# MSP430FR5739 register map
File version: 1.1
CPU: msp430
Registers are 16-bit, access not given, reset 0x0 unless marked. A register's access mark holds for its fields unless they carry their own. Offsets are from the block's base; [hi:lo] are bit positions; {n}, {i} and the like mark numbered series.

## USCI_A0__SPI_Mode
Base 0x00000000
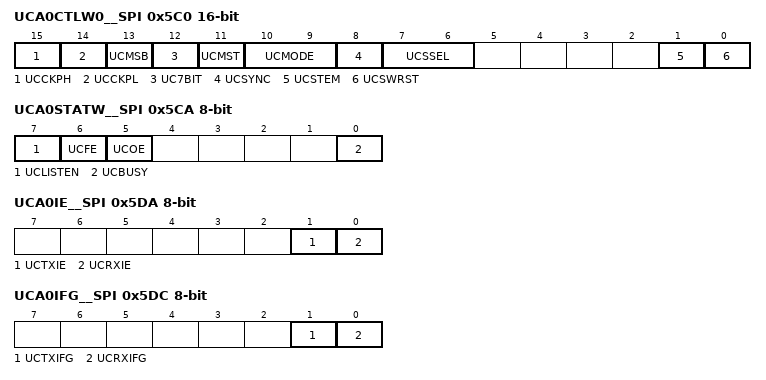
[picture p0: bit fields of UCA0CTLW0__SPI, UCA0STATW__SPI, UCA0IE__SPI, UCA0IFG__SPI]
0x5C0 UCA0CTLW0__SPI — USCI A0 Control Word Register 0
  [15] UCCKPH — [15:15] Sync. Mode: Clock Phase
  [14] UCCKPL — [14:14] Sync. Mode: Clock Polarity
  [13] UCMSB — [13:13] Sync. Mode: MSB first 0:LSB / 1:MSB
  [12] UC7BIT — [12:12] Sync. Mode: Data Bits 0:8-bits / 1:7-bits
  [11] UCMST — [11:11] Sync. Mode: Master Select
  [10:9] UCMODE — [10:9] Sync. Mode: USCI Mode 1
    {v}=Sync. Mode: USCI Mode: {v} (v=0..3)
  [8] UCSYNC — [8:8] Sync-Mode 0:UART-Mode / 1:SPI-Mode
  [7:6] UCSSEL — [7:6] USCI 1 Clock Source Select 1
    {v}=USCI 0 Clock Source: {v} (v=0..3)
  [1] UCSTEM — [1:1] USCI STE Mode
  [0] UCSWRST — [0:0] USCI Software Reset
0x5C0 UCA0CTL1__SPI 8-bit — USCI A0 Control Register 1
0x5C1 UCA0CTL0__SPI 8-bit — USCI A0 Control Register 0
0x5C6 UCA0BRW__SPI — USCI A0 Baud Word Rate 0
0x5C6 UCA0BR0__SPI 8-bit — USCI A0 Baud Rate 0
0x5C7 UCA0BR1__SPI 8-bit — USCI A0 Baud Rate 1
0x5CA UCA0STATW__SPI 8-bit — USCI A0 Status Register
  [7] UCLISTEN — [7:7] USCI Listen mode
  [6] UCFE — [6:6] USCI Frame Error Flag
  [5] UCOE — [5:5] USCI Overrun Error Flag
  [0] UCBUSY — [0:0] USCI Busy Flag
0x5CC UCA0RXBUF__SPI — USCI A0 Receive Buffer
0x5CE UCA0TXBUF__SPI — USCI A0 Transmit Buffer
0x5DA UCA0IE__SPI 8-bit — USCI A0 Interrupt Enable Register
  [1] UCTXIE — [1:1] USCI Transmit Interrupt Enable
  [0] UCRXIE — [0:0] USCI Receive Interrupt Enable
0x5DC UCA0IFG__SPI 8-bit — USCI A0 Interrupt Flags Register
  [1] UCTXIFG — [1:1] SPI Transmit Interrupt Flag
  [0] UCRXIFG — [0:0] SPI Receive Interrupt Flag
0x5DE UCA0IV__SPI — USCI A0 Interrupt Vector Register

## USCI_B0__SPI_Mode
Base 0x00000000
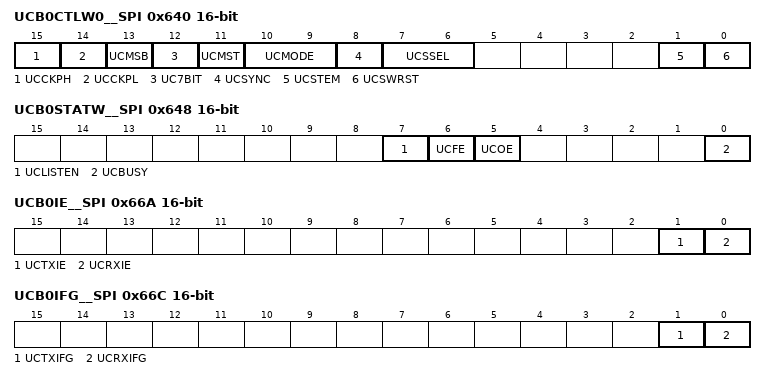
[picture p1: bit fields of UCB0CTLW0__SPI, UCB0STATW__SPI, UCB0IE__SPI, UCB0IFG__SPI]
0x640 UCB0CTLW0__SPI — USCI B0 Control Word Register 0
  [15] UCCKPH — [15:15] Sync. Mode: Clock Phase
  [14] UCCKPL — [14:14] Sync. Mode: Clock Polarity
  [13] UCMSB — [13:13] Sync. Mode: MSB first 0:LSB / 1:MSB
  [12] UC7BIT — [12:12] Sync. Mode: Data Bits 0:8-bits / 1:7-bits
  [11] UCMST — [11:11] Sync. Mode: Master Select
  [10:9] UCMODE — [10:9] Sync. Mode: USCI Mode 1
    {v}=Sync. Mode: USCI Mode: {v} (v=0..3)
  [8] UCSYNC — [8:8] Sync-Mode 0:UART-Mode / 1:SPI-Mode
  [7:6] UCSSEL — [7:6] USCI 1 Clock Source Select 1
    {v}=USCI 0 Clock Source: {v} (v=0..3)
  [1] UCSTEM — [1:1] USCI STE Mode
  [0] UCSWRST — [0:0] USCI Software Reset
0x640 UCB0CTL1__SPI 8-bit — USCI B0 Control Register 1
0x641 UCB0CTL0__SPI 8-bit — USCI B0 Control Register 0
0x646 UCB0BRW__SPI — USCI B0 Baud Word Rate 0
0x646 UCB0BR0__SPI 8-bit — USCI B0 Baud Rate 0
0x647 UCB0BR1__SPI 8-bit — USCI B0 Baud Rate 1
0x648 UCB0STATW__SPI — USCI B0 Status Register
  [7] UCLISTEN — [7:7] USCI Listen mode
  [6] UCFE — [6:6] USCI Frame Error Flag
  [5] UCOE — [5:5] USCI Overrun Error Flag
  [0] UCBUSY — [0:0] USCI Busy Flag
0x64C UCB0RXBUF__SPI — USCI B0 Receive Buffer
0x64E UCB0TXBUF__SPI — USCI B0 Transmit Buffer
0x66A UCB0IE__SPI — USCI B0 Interrupt Enable Register
  [1] UCTXIE — [1:1] USCI Transmit Interrupt Enable
  [0] UCRXIE — [0:0] USCI Receive Interrupt Enable
0x66C UCB0IFG__SPI — USCI B0 Interrupt Flags Register
  [1] UCTXIFG — [1:1] SPI Transmit Interrupt Flag
  [0] UCRXIFG — [0:0] SPI Receive Interrupt Flag
0x66E UCB0IV__SPI — USCI B0 Interrupt Vector Register

## USCI_A1__SPI_Mode
Base 0x00000000
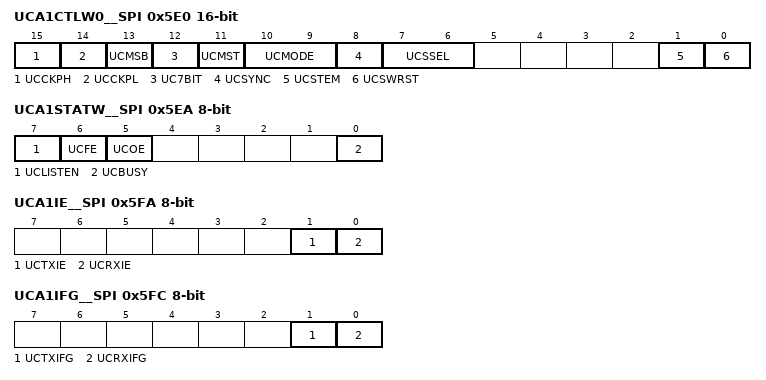
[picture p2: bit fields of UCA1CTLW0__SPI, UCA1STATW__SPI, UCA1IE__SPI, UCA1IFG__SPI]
0x5E0 UCA1CTLW0__SPI — USCI A1 Control Word Register 0
  [15] UCCKPH — [15:15] Sync. Mode: Clock Phase
  [14] UCCKPL — [14:14] Sync. Mode: Clock Polarity
  [13] UCMSB — [13:13] Sync. Mode: MSB first 0:LSB / 1:MSB
  [12] UC7BIT — [12:12] Sync. Mode: Data Bits 0:8-bits / 1:7-bits
  [11] UCMST — [11:11] Sync. Mode: Master Select
  [10:9] UCMODE — [10:9] Sync. Mode: USCI Mode 1
    {v}=Sync. Mode: USCI Mode: {v} (v=0..3)
  [8] UCSYNC — [8:8] Sync-Mode 0:UART-Mode / 1:SPI-Mode
  [7:6] UCSSEL — [7:6] USCI 1 Clock Source Select 1
    {v}=USCI 0 Clock Source: {v} (v=0..3)
  [1] UCSTEM — [1:1] USCI STE Mode
  [0] UCSWRST — [0:0] USCI Software Reset
0x5E0 UCA1CTL1__SPI 8-bit — USCI A1 Control Register 1
0x5E1 UCA1CTL0__SPI 8-bit — USCI A1 Control Register 0
0x5E6 UCA1BRW__SPI — USCI A1 Baud Word Rate 0
0x5E6 UCA1BR0__SPI 8-bit — USCI A1 Baud Rate 0
0x5E7 UCA1BR1__SPI 8-bit — USCI A1 Baud Rate 1
0x5EA UCA1STATW__SPI 8-bit — USCI A1 Status Register
  [7] UCLISTEN — [7:7] USCI Listen mode
  [6] UCFE — [6:6] USCI Frame Error Flag
  [5] UCOE — [5:5] USCI Overrun Error Flag
  [0] UCBUSY — [0:0] USCI Busy Flag
0x5EC UCA1RXBUF__SPI — USCI A1 Receive Buffer
0x5EE UCA1TXBUF__SPI — USCI A1 Transmit Buffer
0x5FA UCA1IE__SPI 8-bit — USCI A1 Interrupt Enable Register
  [1] UCTXIE — [1:1] USCI Transmit Interrupt Enable
  [0] UCRXIE — [0:0] USCI Receive Interrupt Enable
0x5FC UCA1IFG__SPI 8-bit — USCI A1 Interrupt Flags Register
  [1] UCTXIFG — [1:1] SPI Transmit Interrupt Flag
  [0] UCRXIFG — [0:0] SPI Receive Interrupt Flag
0x5FE UCA1IV__SPI — USCI A1 Interrupt Vector Register

## Watchdog_Timer
Base 0x00000000
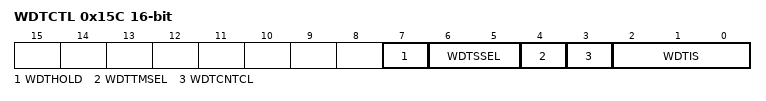
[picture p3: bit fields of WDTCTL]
0x15C WDTCTL — Watchdog Timer Control
  [7] WDTHOLD — [7:7] WDT - Timer hold
  [6:5] WDTSSEL — [6:5] WDT - Timer Clock Source Select 0
    0=WDT - Timer Clock Source Select: SMCLK; 1=WDT - Timer Clock Source Select: ACLK; 2=WDT - Timer Clock Source Select: VLO_CLK; 3=WDT - Timer Clock Source Select: reserved
  [4] WDTTMSEL — [4:4] WDT - Timer Mode Select
  [3] WDTCNTCL — [3:3] WDT - Timer Clear
  [2:0] WDTIS — [2:0] WDT - Timer Interval Select 0
    0=WDT - Timer Interval Select: /2G; 1=WDT - Timer Interval Select: /128M; 2=WDT - Timer Interval Select: /8192k; 3=WDT - Timer Interval Select: /512k; 4=WDT - Timer Interval Select: /32k; 5=WDT - Timer Interval Select: /8192; 6=WDT - Timer Interval Select: /512; 7=WDT - Timer Interval Select: /64
